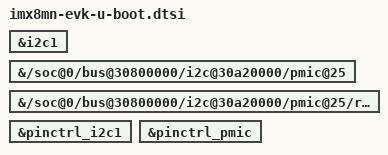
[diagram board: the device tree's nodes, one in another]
// SPDX-License-Identifier: GPL-2.0+
/*
 * Copyright 2019 NXP
 */

#include "imx8mn-ddr4-evk-u-boot.dtsi"

&i2c1 {
	bootph-pre-ram;
};

&{/soc@0/bus@30800000/i2c@30a20000/pmic@25} {
	bootph-pre-ram;
};

&{/soc@0/bus@30800000/i2c@30a20000/pmic@25/regulators} {
	bootph-pre-ram;
};

&pinctrl_i2c1 {
	bootph-pre-ram;
};

&pinctrl_pmic {
	bootph-pre-ram;
};
